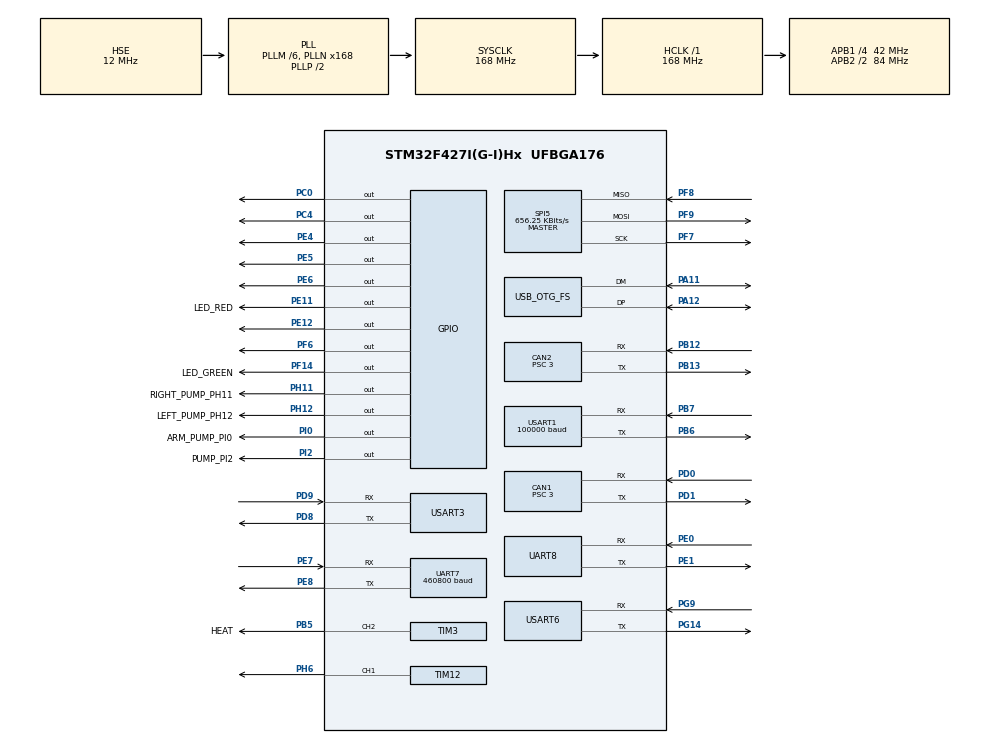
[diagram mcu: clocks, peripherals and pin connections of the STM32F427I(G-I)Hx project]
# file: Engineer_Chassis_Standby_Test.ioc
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CAN1.ABOM=ENABLE
CAN1.AWUM=ENABLE
CAN1.BS1=CAN_BS1_7TQ
CAN1.BS2=CAN_BS2_6TQ
CAN1.CalculateBaudRate=1000000
CAN1.CalculateTimeBit=1000
CAN1.CalculateTimeQuantum=71.42857142857143
CAN1.NART=ENABLE
CAN1.Prescaler=3
CAN1.TXFP=ENABLE
CAN2.ABOM=ENABLE
CAN2.AWUM=ENABLE
CAN2.BS1=CAN_BS1_7TQ
CAN2.BS2=CAN_BS2_6TQ
CAN2.CalculateBaudRate=1000000
CAN2.CalculateTimeBit=1000
CAN2.CalculateTimeQuantum=71.42857142857143
CAN2.NART=ENABLE
CAN2.Prescaler=3
CAN2.TXFP=ENABLE
Dma.Request0=USART1_RX
Dma.Request1=SPI5_RX
Dma.Request2=SPI5_TX
Dma.Request3=UART7_RX
Dma.Request4=UART8_RX
Dma.Request5=UART8_TX
Dma.Request6=USART3_RX
Dma.Request7=USART3_TX
Dma.Request8=USART6_RX
Dma.Request9=USART6_TX
Dma.SPI5_RX.1.Direction=DMA_PERIPH_TO_MEMORY
Dma.SPI5_RX.1.FIFOMode=DMA_FIFOMODE_DISABLE
Dma.SPI5_RX.1.Instance=DMA2_Stream3
Dma.SPI5_RX.1.MemDataAlignment=DMA_MDATAALIGN_BYTE
Dma.SPI5_RX.1.MemInc=DMA_MINC_ENABLE
Dma.SPI5_RX.1.Mode=DMA_NORMAL
Dma.SPI5_RX.1.PeriphDataAlignment=DMA_PDATAALIGN_BYTE
Dma.SPI5_RX.1.PeriphInc=DMA_PINC_DISABLE
Dma.SPI5_RX.1.Priority=DMA_PRIORITY_HIGH
Dma.SPI5_TX.2.Direction=DMA_MEMORY_TO_PERIPH
Dma.SPI5_TX.2.FIFOMode=DMA_FIFOMODE_DISABLE
Dma.SPI5_TX.2.Instance=DMA2_Stream4
Dma.SPI5_TX.2.MemDataAlignment=DMA_MDATAALIGN_BYTE
Dma.SPI5_TX.2.MemInc=DMA_MINC_ENABLE
Dma.SPI5_TX.2.Mode=DMA_NORMAL
Dma.SPI5_TX.2.PeriphDataAlignment=DMA_PDATAALIGN_BYTE
Dma.SPI5_TX.2.PeriphInc=DMA_PINC_DISABLE
Dma.SPI5_TX.2.Priority=DMA_PRIORITY_HIGH
Dma.UART7_RX.3.Direction=DMA_PERIPH_TO_MEMORY
Dma.UART7_RX.3.FIFOMode=DMA_FIFOMODE_DISABLE
Dma.UART7_RX.3.Instance=DMA1_Stream3
Dma.UART7_RX.3.MemDataAlignment=DMA_MDATAALIGN_BYTE
Dma.UART7_RX.3.MemInc=DMA_MINC_ENABLE
Dma.UART7_RX.3.Mode=DMA_NORMAL
Dma.UART7_RX.3.PeriphDataAlignment=DMA_PDATAALIGN_BYTE
Dma.UART7_RX.3.PeriphInc=DMA_PINC_DISABLE
Dma.UART7_RX.3.Priority=DMA_PRIORITY_HIGH
Dma.UART8_RX.4.Direction=DMA_PERIPH_TO_MEMORY
Dma.UART8_RX.4.FIFOMode=DMA_FIFOMODE_DISABLE
Dma.UART8_RX.4.Instance=DMA1_Stream6
Dma.UART8_RX.4.MemDataAlignment=DMA_MDATAALIGN_BYTE
Dma.UART8_RX.4.MemInc=DMA_MINC_ENABLE
Dma.UART8_RX.4.Mode=DMA_CIRCULAR
Dma.UART8_RX.4.PeriphDataAlignment=DMA_PDATAALIGN_BYTE
Dma.UART8_RX.4.PeriphInc=DMA_PINC_DISABLE
Dma.UART8_RX.4.Priority=DMA_PRIORITY_HIGH
Dma.UART8_TX.5.Direction=DMA_MEMORY_TO_PERIPH
Dma.UART8_TX.5.FIFOMode=DMA_FIFOMODE_DISABLE
Dma.UART8_TX.5.Instance=DMA1_Stream0
Dma.UART8_TX.5.MemDataAlignment=DMA_MDATAALIGN_BYTE
Dma.UART8_TX.5.MemInc=DMA_MINC_ENABLE
Dma.UART8_TX.5.Mode=DMA_NORMAL
Dma.UART8_TX.5.PeriphDataAlignment=DMA_PDATAALIGN_BYTE
Dma.UART8_TX.5.PeriphInc=DMA_PINC_DISABLE
Dma.UART8_TX.5.Priority=DMA_PRIORITY_HIGH
Dma.USART1_RX.0.Direction=DMA_PERIPH_TO_MEMORY
Dma.USART1_RX.0.FIFOMode=DMA_FIFOMODE_DISABLE
Dma.USART1_RX.0.Instance=DMA2_Stream2
Dma.USART1_RX.0.MemDataAlignment=DMA_MDATAALIGN_BYTE
Dma.USART1_RX.0.MemInc=DMA_MINC_ENABLE
Dma.USART1_RX.0.Mode=DMA_NORMAL
Dma.USART1_RX.0.PeriphDataAlignment=DMA_PDATAALIGN_BYTE
Dma.USART1_RX.0.PeriphInc=DMA_PINC_DISABLE
Dma.USART1_RX.0.Priority=DMA_PRIORITY_HIGH
Dma.USART3_RX.6.Direction=DMA_PERIPH_TO_MEMORY
Dma.USART3_RX.6.FIFOMode=DMA_FIFOMODE_DISABLE
Dma.USART3_RX.6.Instance=DMA1_Stream1
Dma.USART3_RX.6.MemDataAlignment=DMA_MDATAALIGN_BYTE
Dma.USART3_RX.6.MemInc=DMA_MINC_ENABLE
Dma.USART3_RX.6.Mode=DMA_CIRCULAR
Dma.USART3_RX.6.PeriphDataAlignment=DMA_PDATAALIGN_BYTE
Dma.USART3_RX.6.PeriphInc=DMA_PINC_DISABLE
Dma.USART3_RX.6.Priority=DMA_PRIORITY_HIGH
Dma.USART3_TX.7.Direction=DMA_MEMORY_TO_PERIPH
Dma.USART3_TX.7.FIFOMode=DMA_FIFOMODE_DISABLE
Dma.USART3_TX.7.Instance=DMA1_Stream4
Dma.USART3_TX.7.MemDataAlignment=DMA_MDATAALIGN_BYTE
Dma.USART3_TX.7.MemInc=DMA_MINC_ENABLE
Dma.USART3_TX.7.Mode=DMA_NORMAL
Dma.USART3_TX.7.PeriphDataAlignment=DMA_PDATAALIGN_BYTE
Dma.USART3_TX.7.PeriphInc=DMA_PINC_DISABLE
Dma.USART3_TX.7.Priority=DMA_PRIORITY_HIGH
Dma.USART6_RX.8.Direction=DMA_PERIPH_TO_MEMORY
Dma.USART6_RX.8.FIFOMode=DMA_FIFOMODE_DISABLE
Dma.USART6_RX.8.Instance=DMA2_Stream1
Dma.USART6_RX.8.MemDataAlignment=DMA_MDATAALIGN_BYTE
Dma.USART6_RX.8.MemInc=DMA_MINC_ENABLE
Dma.USART6_RX.8.Mode=DMA_NORMAL
Dma.USART6_RX.8.PeriphDataAlignment=DMA_PDATAALIGN_BYTE
Dma.USART6_RX.8.PeriphInc=DMA_PINC_DISABLE
Dma.USART6_RX.8.Priority=DMA_PRIORITY_HIGH
Dma.USART6_TX.9.Direction=DMA_MEMORY_TO_PERIPH
Dma.USART6_TX.9.FIFOMode=DMA_FIFOMODE_DISABLE
Dma.USART6_TX.9.Instance=DMA2_Stream6
Dma.USART6_TX.9.MemDataAlignment=DMA_MDATAALIGN_BYTE
Dma.USART6_TX.9.MemInc=DMA_MINC_ENABLE
Dma.USART6_TX.9.Mode=DMA_NORMAL
Dma.USART6_TX.9.PeriphDataAlignment=DMA_PDATAALIGN_BYTE
Dma.USART6_TX.9.PeriphInc=DMA_PINC_DISABLE
Dma.USART6_TX.9.Priority=DMA_PRIORITY_HIGH
FREERTOS.BinarySemaphores01=ChassisLFUpdateBinarySem,Dynamic,NULL,Depleted;ChassisLBUpdateBinarySem,Dynamic,NULL,Depleted;ChassisRBUpdateBinarySem,Dynamic,NULL,Depleted;ChassisRFUpdateBinarySem,Dynamic,NULL,Depleted;HI229UMRxBinarySem,Dynamic,NULL,Depleted;TofUpdateBinarySem,Dynamic,NULL,Depleted;GimbalYawUpdateBinarySem,Dynamic,NULL,Depleted;GimbalSlideUpdateBinarySem,Dynamic,NULL,Depleted;ServoCtrlTXBinarySem,Dynamic,NULL,Available;AbsorbUpdateBinarySem,Dynamic,NULL,Available;GimbalToChassisUpdateBinarySem,Dynamic,NULL,Depleted
FREERTOS.CountingSemaphores01=CAN1CountingSem,3,Dynamic,NULL,3;CAN2CountingSem,3,Dynamic,NULL,3
FREERTOS.Queues01=CAN1SendQueue,64,can_tx_member_t,0,Dynamic,NULL,NULL;CAN2SendQueue,64,can_tx_member_t,0,Dynamic,NULL,NULL;ServoCtrlQueue,16,servo_ctrl_data_t,0,Dynamic,NULL,NULL
FREERTOS.Tasks01=defaultTask,24,128,StartDefaultTask,Default,NULL,Dynamic,NULL,NULL;can1_Task,40,256,CAN1_Task,As weak,NULL,Dynamic,NULL,NULL;can2_Task,40,256,CAN2_Task,As weak,NULL,Dynamic,NULL,NULL;chassis_Task,24,256,Chassis_Task,As weak,NULL,Dynamic,NULL,NULL;hi229um_Task,24,128,HI229UM_Task,As weak,NULL,Dynamic,NULL,NULL;tof_check_Task,24,128,Tof_Check_Task,As weak,NULL,Dynamic,NULL,NULL;motor_check,24,128,Motor_Check_Task,As weak,NULL,Dynamic,NULL,NULL;servo_ctrl_Task,24,128,Servo_Ctrl_Task,As weak,NULL,Dynamic,NULL,NULL;gimbal_slide,24,128,Gimbal_Slide_Task,As weak,NULL,Dynamic,NULL,NULL;gimbal_attitude,24,256,Gimbal_Attitude_Task,As weak,NULL,Dynamic,NULL,NULL;info_Task,24,256,Info_Task,As weak,NULL,Dynamic,NULL,NULL;absorb_Task,24,128,Absorb_Task,As weak,NULL,Dynamic,NULL,NULL;check_communi,24,128,Check_Communicate_Task,As weak,NULL,Dynamic,NULL,NULL;communicat_Task,24,128,Communication_Task,As weak,NULL,Dynamic,NULL,NULL
FREERTOS.configTOTAL_HEAP_SIZE=120000
FREERTOS.configUSE_NEWLIB_REENTRANT=1
IWDG.Prescaler=IWDG_PRESCALER_64
IWDG.Reload=625
Mcu.Family=STM32F4
Mcu.Name=STM32F427I(G-I)Hx
Mcu.Package=UFBGA176
NVIC.CAN1_RX0_IRQn=true\:5\:0\:false\:false\:true\:true\:true\:true\:true
NVIC.CAN1_TX_IRQn=true\:5\:0\:false\:false\:true\:true\:true\:true\:true
NVIC.CAN2_RX1_IRQn=true\:5\:0\:false\:false\:true\:true\:true\:true\:true
NVIC.CAN2_TX_IRQn=true\:5\:0\:false\:false\:true\:true\:true\:true\:true
NVIC.DMA1_Stream0_IRQn=true\:5\:0\:false\:false\:true\:true\:false\:true\:true
NVIC.DMA1_Stream1_IRQn=true\:5\:0\:false\:false\:true\:true\:false\:true\:true
NVIC.DMA1_Stream3_IRQn=true\:5\:0\:false\:false\:true\:true\:false\:true\:true
NVIC.DMA1_Stream4_IRQn=true\:5\:0\:false\:false\:true\:true\:false\:true\:true
NVIC.DMA1_Stream6_IRQn=true\:5\:0\:false\:false\:true\:true\:false\:true\:true
NVIC.DMA2_Stream1_IRQn=true\:5\:0\:false\:false\:true\:true\:false\:true\:true
NVIC.DMA2_Stream2_IRQn=true\:5\:0\:false\:false\:true\:true\:false\:true\:true
NVIC.DMA2_Stream3_IRQn=true\:5\:0\:false\:false\:true\:true\:false\:true\:true
NVIC.DMA2_Stream4_IRQn=true\:5\:0\:false\:false\:true\:true\:false\:true\:true
NVIC.DMA2_Stream6_IRQn=true\:5\:0\:false\:false\:true\:true\:false\:true\:true
NVIC.PriorityGroup=NVIC_PRIORITYGROUP_4
NVIC.SPI5_IRQn=true\:5\:0\:false\:false\:true\:true\:true\:true\:true
NVIC.TIM7_IRQn=true\:15\:0\:false\:false\:true\:false\:false\:true\:true
NVIC.TimeBase=TIM7_IRQn
NVIC.TimeBaseIP=TIM7
NVIC.UART7_IRQn=true\:5\:0\:false\:false\:true\:true\:true\:true\:true
NVIC.UART8_IRQn=true\:5\:0\:false\:false\:true\:true\:true\:true\:true
NVIC.USART1_IRQn=true\:5\:0\:false\:false\:true\:true\:true\:true\:true
NVIC.USART3_IRQn=true\:5\:0\:false\:false\:true\:true\:true\:true\:true
NVIC.USART6_IRQn=true\:5\:0\:false\:false\:true\:true\:true\:true\:true
PA11.Mode=Device_Only
PA11.Signal=USB_OTG_FS_DM
PA12.Mode=Device_Only
PA12.Signal=USB_OTG_FS_DP
PA13.Mode=Serial_Wire
PA13.Signal=SYS_JTMS-SWDIO
PA14.Mode=Serial_Wire
PA14.Signal=SYS_JTCK-SWCLK
PB12.Mode=CAN_Activate
PB12.Signal=CAN2_RX
PB13.Mode=CAN_Activate
PB13.Signal=CAN2_TX
PB5.GPIO_Label=HEAT
PB5.GPIO_PuPd=GPIO_PULLUP
PB5.GPIO_Speed=GPIO_SPEED_FREQ_HIGH
PB5.Signal=S_TIM3_CH2
PB6.Mode=Asynchronous
PB6.Signal=USART1_TX
PB7.Mode=Asynchronous
PB7.Signal=USART1_RX
PC0.GPIO_PuPd=GPIO_PULLUP
PC0.GPIO_Speed=GPIO_SPEED_FREQ_HIGH
PC0.Signal=GPIO_Output
PC4.GPIO_PuPd=GPIO_PULLUP
PC4.GPIO_Speed=GPIO_SPEED_FREQ_HIGH
PC4.Signal=GPIO_Output
PD0.Mode=CAN_Activate
PD0.Signal=CAN1_RX
PD1.Mode=CAN_Activate
PD1.Signal=CAN1_TX
PD8.Mode=Asynchronous
PD8.Signal=USART3_TX
PD9.Mode=Asynchronous
PD9.Signal=USART3_RX
PE0.Mode=Asynchronous
PE0.Signal=UART8_RX
PE1.Mode=Asynchronous
PE1.Signal=UART8_TX
PE11.GPIO_Label=LED_RED
PE11.PinState=GPIO_PIN_SET
PE11.Signal=GPIO_Output
PE12.GPIO_PuPd=GPIO_PULLUP
PE12.GPIO_Speed=GPIO_SPEED_FREQ_HIGH
PE12.Signal=GPIO_Output
PE4.GPIO_PuPd=GPIO_PULLUP
PE4.GPIO_Speed=GPIO_SPEED_FREQ_HIGH
PE4.Signal=GPIO_Output
PE5.GPIO_PuPd=GPIO_PULLUP
PE5.GPIO_Speed=GPIO_SPEED_FREQ_HIGH
PE5.Signal=GPIO_Output
PE6.GPIO_PuPd=GPIO_PULLUP
PE6.GPIO_Speed=GPIO_SPEED_FREQ_HIGH
PE6.Signal=GPIO_Output
PE7.Mode=Asynchronous
PE7.Signal=UART7_RX
PE8.Mode=Asynchronous
PE8.Signal=UART7_TX
PF14.GPIO_Label=LED_GREEN
PF14.Signal=GPIO_Output
PF6.Signal=GPIO_Output
PF7.Mode=Full_Duplex_Master
PF7.Signal=SPI5_SCK
PF8.Mode=Full_Duplex_Master
PF8.Signal=SPI5_MISO
PF9.Mode=Full_Duplex_Master
PF9.Signal=SPI5_MOSI
PG14.Mode=Asynchronous
PG14.Signal=USART6_TX
PG9.Mode=Asynchronous
PG9.Signal=USART6_RX
PH0/OSC_IN.Mode=HSE-External-Oscillator
PH0/OSC_IN.Signal=RCC_OSC_IN
PH1/OSC_OUT.Mode=HSE-External-Oscillator
PH1/OSC_OUT.Signal=RCC_OSC_OUT
PH11.GPIO_Label=RIGHT_PUMP_PH11
PH11.GPIO_Speed=GPIO_SPEED_FREQ_HIGH
PH11.Signal=GPIO_Output
PH12.GPIO_Label=LEFT_PUMP_PH12
PH12.GPIO_Speed=GPIO_SPEED_FREQ_HIGH
PH12.Signal=GPIO_Output
PH6.Signal=S_TIM12_CH1
PI0.GPIO_Label=ARM_PUMP_PI0
PI0.Signal=GPIO_Output
PI2.GPIO_Label=PUMP_PI2
PI2.Signal=GPIO_Output
ProjectManager.HeapSize=0x1000
ProjectManager.StackSize=0x1000
ProjectManager.TargetToolchain=STM32CubeIDE
RCC.48MHZClocksFreq_Value=48000000
RCC.AHBFreq_Value=168000000
RCC.APB1CLKDivider=RCC_HCLK_DIV4
RCC.APB1Freq_Value=42000000
RCC.APB1TimFreq_Value=84000000
RCC.APB2CLKDivider=RCC_HCLK_DIV2
RCC.APB2Freq_Value=84000000
RCC.APB2TimFreq_Value=168000000
RCC.CortexFreq_Value=168000000
RCC.HCLKFreq_Value=168000000
RCC.HSE_VALUE=12000000
RCC.HSI_VALUE=16000000
RCC.LSE_VALUE=32768
RCC.PLLM=6
RCC.PLLN=168
RCC.PLLQ=7
RCC.SYSCLKFreq_VALUE=168000000
RCC.SYSCLKSource=RCC_SYSCLKSOURCE_PLLCLK
RCC.VCOOutputFreq_Value=336000000
SH.S_TIM12_CH1.0=TIM12_CH1,PWM Generation1 CH1
SH.S_TIM3_CH2.0=TIM3_CH2,PWM Generation2 CH2
SPI5.BaudRatePrescaler=SPI_BAUDRATEPRESCALER_128
SPI5.CalculateBaudRate=656.25 KBits/s
SPI5.Direction=SPI_DIRECTION_2LINES
SPI5.Mode=SPI_MODE_MASTER
SPI5.VirtualType=VM_MASTER
TIM12.Channel-PWM\ Generation1\ CH1=TIM_CHANNEL_1
TIM12.Period=369
TIM12.Prescaler=83
TIM3.Channel-PWM\ Generation2\ CH2=TIM_CHANNEL_2
TIM3.Period=9999
UART7.BaudRate=460800
UART7.VirtualMode=Asynchronous
UART8.VirtualMode=Asynchronous
USART1.BaudRate=100000
USART1.Parity=PARITY_EVEN
USART1.VirtualMode=VM_ASYNC
USART1.WordLength=WORDLENGTH_9B
USART3.VirtualMode=VM_ASYNC
USART6.VirtualMode=VM_ASYNC
USB_OTG_FS.VirtualMode=Device_Only
VP_FREERTOS_VS_CMSIS_V2.Mode=CMSIS_V2
VP_IWDG_VS_IWDG.Mode=IWDG_Activate
VP_SYS_VS_tim7.Mode=TIM7
VP_TIM12_VS_ClockSourceINT.Mode=Internal
board=custom

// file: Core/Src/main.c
/* USER CODE BEGIN Header */
/**
  ******************************************************************************
  * @file           : main.c
  * @brief          : Main program body
  ******************************************************************************
  * @attention
  *
  * Copyright (c) 2024 STMicroelectronics.
  * All rights reserved.
  *
  * This software is licensed under terms that can be found in the LICENSE file
  * in the root directory of this software component.
  * If no LICENSE file comes with this software, it is provided AS-IS.
  *
  ******************************************************************************
  */
/* USER CODE END Header */
#include "main.h"
#include "cmsis_os.h"
#include "can.h"
#include "dma.h"
#include "iwdg.h"
#include "spi.h"
#include "tim.h"
#include "usart.h"
#include "usb_otg.h"
#include "gpio.h"

/* USER CODE BEGIN Includes */
#include "Compilable.h"
#include "RTOS.h"
/* USER CODE END Includes */

void SystemClock_Config(void);
void MX_FREERTOS_Init(void);

int main(void)
{

  /* USER CODE BEGIN 1 */
  __HAL_RCC_SYSCLK_CONFIG(RCC_SYSCLKSOURCE_HSI);
  /* USER CODE END 1 */

  /* MCU Configuration--------------------------------------------------------*/

  /* Reset of all peripherals, Initializes the Flash interface and the Systick. */
  HAL_Init();

  /* Configure the system clock */
  SystemClock_Config();

  /* Initialize all configured peripherals */
  MX_GPIO_Init();
  MX_DMA_Init();
  MX_USART1_UART_Init();
  MX_TIM12_Init();
  MX_CAN1_Init();
  MX_CAN2_Init();
  MX_SPI5_Init();
  MX_TIM3_Init();
  MX_UART7_Init();
  MX_UART8_Init();
  MX_USART3_UART_Init();
  MX_USART6_UART_Init();
  MX_IWDG_Init();
  MX_USB_OTG_FS_PCD_Init();
  /* USER CODE BEGIN 2 */
  BSP_CAN_Init();
  /* USER CODE END 2 */

  /* Init scheduler */
  osKernelInitialize();

  /* Call init function for freertos objects (in cmsis_os2.c) */
  MX_FREERTOS_Init();

  /* Start scheduler */
  osKernelStart();

  /* We should never get here as control is now taken by the scheduler */

  /* Infinite loop */
  while (1)
  {

  }
}

void SystemClock_Config(void)
{
  RCC_OscInitTypeDef RCC_OscInitStruct = {0};
  RCC_ClkInitTypeDef RCC_ClkInitStruct = {0};

  /** Configure the main internal regulator output voltage
  */
  __HAL_RCC_PWR_CLK_ENABLE();
  __HAL_PWR_VOLTAGESCALING_CONFIG(PWR_REGULATOR_VOLTAGE_SCALE1);

  /** Initializes the RCC Oscillators according to the specified parameters
  * in the RCC_OscInitTypeDef structure.
  */
  RCC_OscInitStruct.OscillatorType = RCC_OSCILLATORTYPE_LSI|RCC_OSCILLATORTYPE_HSE;
  RCC_OscInitStruct.HSEState = RCC_HSE_ON;
  RCC_OscInitStruct.LSIState = RCC_LSI_ON;
  RCC_OscInitStruct.PLL.PLLState = RCC_PLL_ON;
  RCC_OscInitStruct.PLL.PLLSource = RCC_PLLSOURCE_HSE;
  RCC_OscInitStruct.PLL.PLLM = 6;
  RCC_OscInitStruct.PLL.PLLN = 168;
  RCC_OscInitStruct.PLL.PLLP = RCC_PLLP_DIV2;
  RCC_OscInitStruct.PLL.PLLQ = 7;
  if (HAL_RCC_OscConfig(&RCC_OscInitStruct) != HAL_OK)
  {
    Error_Handler();
  }

  /** Initializes the CPU, AHB and APB buses clocks
  */
  RCC_ClkInitStruct.ClockType = RCC_CLOCKTYPE_HCLK|RCC_CLOCKTYPE_SYSCLK
                              |RCC_CLOCKTYPE_PCLK1|RCC_CLOCKTYPE_PCLK2;
  RCC_ClkInitStruct.SYSCLKSource = RCC_SYSCLKSOURCE_PLLCLK;
  RCC_ClkInitStruct.AHBCLKDivider = RCC_SYSCLK_DIV1;
  RCC_ClkInitStruct.APB1CLKDivider = RCC_HCLK_DIV4;
  RCC_ClkInitStruct.APB2CLKDivider = RCC_HCLK_DIV2;

  if (HAL_RCC_ClockConfig(&RCC_ClkInitStruct, FLASH_LATENCY_5) != HAL_OK)
  {
    Error_Handler();
  }
}

void HAL_TIM_PeriodElapsedCallback(TIM_HandleTypeDef *htim)
{
  if (htim->Instance == TIM7) {
    HAL_IncTick();
  }
}

void Error_Handler(void)
{
  __disable_irq();
  while (1)
  {
  }
}

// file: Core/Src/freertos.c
/* USER CODE BEGIN Header */
/**
  ******************************************************************************
  * File Name          : freertos.c
  * Description        : Code for freertos applications
  ******************************************************************************
  * @attention
  *
  * Copyright (c) 2024 STMicroelectronics.
  * All rights reserved.
  *
  * This software is licensed under terms that can be found in the LICENSE file
  * in the root directory of this software component.
  * If no LICENSE file comes with this software, it is provided AS-IS.
  *
  ******************************************************************************
  */
/* USER CODE END Header */

#include "FreeRTOS.h"
#include "task.h"
#include "main.h"
#include "cmsis_os.h"

/* USER CODE BEGIN Includes */
#include "Compilable.h"
#include "iwdg.h"
/* USER CODE END Includes */

/* Definitions for defaultTask */
osThreadId_t defaultTaskHandle;
const osThreadAttr_t defaultTask_attributes = {
  .name = "defaultTask",
  .stack_size = 128 * 4,
  .priority = (osPriority_t) osPriorityNormal,
};
/* Definitions for remotectrl_Task */
osThreadId_t remotectrl_TaskHandle;
const osThreadAttr_t remotectrl_Task_attributes = {
  .name = "remotectrl_Task",
  .stack_size = 128 * 4,
  .priority = (osPriority_t) osPriorityNormal,
};
/* Definitions for can1_Task */
osThreadId_t can1_TaskHandle;
const osThreadAttr_t can1_Task_attributes = {
  .name = "can1_Task",
  .stack_size = 256 * 4,
  .priority = (osPriority_t) osPriorityHigh,
};
/* Definitions for can2_Task */
osThreadId_t can2_TaskHandle;
const osThreadAttr_t can2_Task_attributes = {
  .name = "can2_Task",
  .stack_size = 256 * 4,
  .priority = (osPriority_t) osPriorityHigh,
};
/* Definitions for chassis_Task */
osThreadId_t chassis_TaskHandle;
const osThreadAttr_t chassis_Task_attributes = {
  .name = "chassis_Task",
  .stack_size = 256 * 4,
  .priority = (osPriority_t) osPriorityNormal,
};
/* Definitions for hi229um_Task */
osThreadId_t hi229um_TaskHandle;
const osThreadAttr_t hi229um_Task_attributes = {
  .name = "hi229um_Task",
  .stack_size = 128 * 4,
  .priority = (osPriority_t) osPriorityNormal,
};
/* Definitions for usb_Task */
osThreadId_t usb_TaskHandle;
const osThreadAttr_t usb_Task_attributes = {
  .name = "usb_Task",
  .stack_size = 512 * 4,
  .priority = (osPriority_t) osPriorityNormal,
};
/* Definitions for tof_check_Task */
osThreadId_t tof_check_TaskHandle;
const osThreadAttr_t tof_check_Task_attributes = {
  .name = "tof_check_Task",
  .stack_size = 128 * 4,
  .priority = (osPriority_t) osPriorityNormal,
};
/* Definitions for motor_check */
osThreadId_t motor_checkHandle;
const osThreadAttr_t motor_check_attributes = {
  .name = "motor_check",
  .stack_size = 128 * 4,
  .priority = (osPriority_t) osPriorityNormal,
};
/* Definitions for servo_ctrl_Task */
osThreadId_t servo_ctrl_TaskHandle;
const osThreadAttr_t servo_ctrl_Task_attributes = {
  .name = "servo_ctrl_Task",
  .stack_size = 128 * 4,
  .priority = (osPriority_t) osPriorityNormal,
};
/* Definitions for gimbal_slide */
osThreadId_t gimbal_slideHandle;
const osThreadAttr_t gimbal_slide_attributes = {
  .name = "gimbal_slide",
  .stack_size = 128 * 4,
  .priority = (osPriority_t) osPriorityNormal,
};
/* Definitions for gimbal_attitude */
osThreadId_t gimbal_attitudeHandle;
const osThreadAttr_t gimbal_attitude_attributes = {
  .name = "gimbal_attitude",
  .stack_size = 256 * 4,
  .priority = (osPriority_t) osPriorityNormal,
};
/* Definitions for info_Task */
osThreadId_t info_TaskHandle;
const osThreadAttr_t info_Task_attributes = {
  .name = "info_Task",
  .stack_size = 256 * 4,
  .priority = (osPriority_t) osPriorityNormal,
};
/* Definitions for kb_state_Task */
osThreadId_t kb_state_TaskHandle;
const osThreadAttr_t kb_state_Task_attributes = {
  .name = "kb_state_Task",
  .stack_size = 128 * 4,
  .priority = (osPriority_t) osPriorityNormal,
};
/* Definitions for kb_event_Task */
osThreadId_t kb_event_TaskHandle;
const osThreadAttr_t kb_event_Task_attributes = {
  .name = "kb_event_Task",
  .stack_size = 128 * 4,
  .priority = (osPriority_t) osPriorityNormal,
};
/* Definitions for absorb_Task */
osThreadId_t absorb_TaskHandle;
const osThreadAttr_t absorb_Task_attributes = {
  .name = "absorb_Task",
  .stack_size = 128 * 4,
  .priority = (osPriority_t) osPriorityNormal,
};
/* Definitions for arm_Task */
osThreadId_t arm_TaskHandle;
const osThreadAttr_t arm_Task_attributes = {
  .name = "arm_Task",
  .stack_size = 128 * 4,
  .priority = (osPriority_t) osPriorityNormal,
};
/* Definitions for check_communi */
osThreadId_t check_communiHandle;
const osThreadAttr_t check_communi_attributes = {
  .name = "check_communi",
  .stack_size = 128 * 4,
  .priority = (osPriority_t) osPriorityNormal,
};
/* Definitions for autoctrl_Task */
osThreadId_t autoctrl_TaskHandle;
const osThreadAttr_t autoctrl_Task_attributes = {
  .name = "autoctrl_Task",
  .stack_size = 256 * 4,
  .priority = (osPriority_t) osPriorityNormal,
};
/* Definitions for gyro_info_Task */
osThreadId_t gyro_info_TaskHandle;
const osThreadAttr_t gyro_info_Task_attributes = {
  .name = "gyro_info_Task",
  .stack_size = 128 * 4,
  .priority = (osPriority_t) osPriorityNormal,
};
/* Definitions for CAN1SendQueue */
osMessageQueueId_t CAN1SendQueueHandle;
const osMessageQueueAttr_t CAN1SendQueue_attributes = {
  .name = "CAN1SendQueue"
};
/* Definitions for CAN2SendQueue */
osMessageQueueId_t CAN2SendQueueHandle;
const osMessageQueueAttr_t CAN2SendQueue_attributes = {
  .name = "CAN2SendQueue"
};
/* Definitions for ServoCtrlQueue */
osMessageQueueId_t ServoCtrlQueueHandle;
const osMessageQueueAttr_t ServoCtrlQueue_attributes = {
  .name = "ServoCtrlQueue"
};
/* Definitions for RCUpdateBinarySem */
osSemaphoreId_t RCUpdateBinarySemHandle;
const osSemaphoreAttr_t RCUpdateBinarySem_attributes = {
  .name = "RCUpdateBinarySem"
};
/* Definitions for ChassisLFUpdateBinarySem */
osSemaphoreId_t ChassisLFUpdateBinarySemHandle;
const osSemaphoreAttr_t ChassisLFUpdateBinarySem_attributes = {
  .name = "ChassisLFUpdateBinarySem"
};
/* Definitions for ChassisLBUpdateBinarySem */
osSemaphoreId_t ChassisLBUpdateBinarySemHandle;
const osSemaphoreAttr_t ChassisLBUpdateBinarySem_attributes = {
  .name = "ChassisLBUpdateBinarySem"
};
/* Definitions for ChassisRBUpdateBinarySem */
osSemaphoreId_t ChassisRBUpdateBinarySemHandle;
const osSemaphoreAttr_t ChassisRBUpdateBinarySem_attributes = {
  .name = "ChassisRBUpdateBinarySem"
};
/* Definitions for ChassisRFUpdateBinarySem */
osSemaphoreId_t ChassisRFUpdateBinarySemHandle;
const osSemaphoreAttr_t ChassisRFUpdateBinarySem_attributes = {
  .name = "ChassisRFUpdateBinarySem"
};
/* Definitions for HI229UMRxBinarySem */
osSemaphoreId_t HI229UMRxBinarySemHandle;
const osSemaphoreAttr_t HI229UMRxBinarySem_attributes = {
  .name = "HI229UMRxBinarySem"
};
/* Definitions for IMUDMABinarySem */
osSemaphoreId_t IMUDMABinarySemHandle;
const osSemaphoreAttr_t IMUDMABinarySem_attributes = {
  .name = "IMUDMABinarySem"
};
/* Definitions for TofUpdateBinarySem */
osSemaphoreId_t TofUpdateBinarySemHandle;
const osSemaphoreAttr_t TofUpdateBinarySem_attributes = {
  .name = "TofUpdateBinarySem"
};
/* Definitions for GimbalYawUpdateBinarySem */
osSemaphoreId_t GimbalYawUpdateBinarySemHandle;
const osSemaphoreAttr_t GimbalYawUpdateBinarySem_attributes = {
  .name = "GimbalYawUpdateBinarySem"
};
/* Definitions for GimbalSlideUpdateBinarySem */
osSemaphoreId_t GimbalSlideUpdateBinarySemHandle;
const osSemaphoreAttr_t GimbalSlideUpdateBinarySem_attributes = {
  .name = "GimbalSlideUpdateBinarySem"
};
/* Definitions for ClawUpdateBinarySem */
osSemaphoreId_t ClawUpdateBinarySemHandle;
const osSemaphoreAttr_t ClawUpdateBinarySem_attributes = {
  .name = "ClawUpdateBinarySem"
};
/* Definitions for ServoCtrlTXBinarySem */
osSemaphoreId_t ServoCtrlTXBinarySemHandle;
const osSemaphoreAttr_t ServoCtrlTXBinarySem_attributes = {
  .name = "ServoCtrlTXBinarySem"
};
/* Definitions for AbsorbUpdateBinarySem */
osSemaphoreId_t AbsorbUpdateBinarySemHandle;
const osSemaphoreAttr_t AbsorbUpdateBinarySem_attributes = {
  .name = "AbsorbUpdateBinarySem"
};
/* Definitions for ArmResetInitBinarySem */
osSemaphoreId_t ArmResetInitBinarySemHandle;
const osSemaphoreAttr_t ArmResetInitBinarySem_attributes = {
  .name = "ArmResetInitBinarySem"
};
/* Definitions for ArmUpdateBinarySem */
osSemaphoreId_t ArmUpdateBinarySemHandle;
const osSemaphoreAttr_t ArmUpdateBinarySem_attributes = {
  .name = "ArmUpdateBinarySem"
};
/* Definitions for JudgementInitBinarySem */
osSemaphoreId_t JudgementInitBinarySemHandle;
const osSemaphoreAttr_t JudgementInitBinarySem_attributes = {
  .name = "JudgementInitBinarySem"
};
/* Definitions for GyroInfoUpdateBinarySem */
osSemaphoreId_t GyroInfoUpdateBinarySemHandle;
const osSemaphoreAttr_t GyroInfoUpdateBinarySem_attributes = {
  .name = "GyroInfoUpdateBinarySem"
};
/* Definitions for CAN1CountingSem */
osSemaphoreId_t CAN1CountingSemHandle;
const osSemaphoreAttr_t CAN1CountingSem_attributes = {
  .name = "CAN1CountingSem"
};
/* Definitions for CAN2CountingSem */
osSemaphoreId_t CAN2CountingSemHandle;
const osSemaphoreAttr_t CAN2CountingSem_attributes = {
  .name = "CAN2CountingSem"
};
/* Definitions for RefereeEvent */
osEventFlagsId_t RefereeEventHandle;
const osEventFlagsAttr_t RefereeEvent_attributes = {
  .name = "RefereeEvent"
};
/* Definitions for refereeEvent */
osEventFlagsId_t refereeEventHandle;
const osEventFlagsAttr_t refereeEvent_attributes = {
  .name = "refereeEvent"
};

void StartDefaultTask(void *argument);
void RemoteCtrl_Task(void *argument);
void CAN1_Task(void *argument);
void CAN2_Task(void *argument);
void Chassis_Task(void *argument);
void HI229UM_Task(void *argument);
void USB_Task(void *argument);
void Tof_Check_Task(void *argument);
void Motor_Check_Task(void *argument);
void Servo_Ctrl_Task(void *argument);
void Gimbal_Slide_Task(void *argument);
void Gimbal_Attitude_Task(void *argument);
void Info_Task(void *argument);
void KB_State_Task(void *argument);
void KB_Event_Task(void *argument);
void Absorb_Task(void *argument);
void Arm_Task(void *argument);
void Check_Communicate_Task(void *argument);
void AutoCtrl_Task(void *argument);
void Gyro_Info_Task(void *argument);

extern void MX_USB_DEVICE_Init(void);
void MX_FREERTOS_Init(void); /* (MISRA C 2004 rule 8.1) */

void MX_FREERTOS_Init(void) {

  /* Create the semaphores(s) */
  /* creation of RCUpdateBinarySem */
  RCUpdateBinarySemHandle = osSemaphoreNew(1, 0, &RCUpdateBinarySem_attributes);

  /* creation of ChassisLFUpdateBinarySem */
  ChassisLFUpdateBinarySemHandle = osSemaphoreNew(1, 0, &ChassisLFUpdateBinarySem_attributes);

  /* creation of ChassisLBUpdateBinarySem */
  ChassisLBUpdateBinarySemHandle = osSemaphoreNew(1, 0, &ChassisLBUpdateBinarySem_attributes);

  /* creation of ChassisRBUpdateBinarySem */
  ChassisRBUpdateBinarySemHandle = osSemaphoreNew(1, 0, &ChassisRBUpdateBinarySem_attributes);

  /* creation of ChassisRFUpdateBinarySem */
  ChassisRFUpdateBinarySemHandle = osSemaphoreNew(1, 0, &ChassisRFUpdateBinarySem_attributes);

  /* creation of HI229UMRxBinarySem */
  HI229UMRxBinarySemHandle = osSemaphoreNew(1, 0, &HI229UMRxBinarySem_attributes);

  /* creation of IMUDMABinarySem */
  IMUDMABinarySemHandle = osSemaphoreNew(1, 0, &IMUDMABinarySem_attributes);

  /* creation of TofUpdateBinarySem */
  TofUpdateBinarySemHandle = osSemaphoreNew(1, 0, &TofUpdateBinarySem_attributes);

  /* creation of GimbalYawUpdateBinarySem */
  GimbalYawUpdateBinarySemHandle = osSemaphoreNew(1, 0, &GimbalYawUpdateBinarySem_attributes);

  /* creation of GimbalSlideUpdateBinarySem */
  GimbalSlideUpdateBinarySemHandle = osSemaphoreNew(1, 0, &GimbalSlideUpdateBinarySem_attributes);

  /* creation of ClawUpdateBinarySem */
  ClawUpdateBinarySemHandle = osSemaphoreNew(1, 0, &ClawUpdateBinarySem_attributes);

  /* creation of ServoCtrlTXBinarySem */
  ServoCtrlTXBinarySemHandle = osSemaphoreNew(1, 1, &ServoCtrlTXBinarySem_attributes);

  /* creation of AbsorbUpdateBinarySem */
  AbsorbUpdateBinarySemHandle = osSemaphoreNew(1, 1, &AbsorbUpdateBinarySem_attributes);

  /* creation of ArmResetInitBinarySem */
  ArmResetInitBinarySemHandle = osSemaphoreNew(1, 1, &ArmResetInitBinarySem_attributes);

  /* creation of ArmUpdateBinarySem */
  ArmUpdateBinarySemHandle = osSemaphoreNew(1, 1, &ArmUpdateBinarySem_attributes);

  /* creation of JudgementInitBinarySem */
  JudgementInitBinarySemHandle = osSemaphoreNew(1, 1, &JudgementInitBinarySem_attributes);

  /* creation of GyroInfoUpdateBinarySem */
  GyroInfoUpdateBinarySemHandle = osSemaphoreNew(1, 1, &GyroInfoUpdateBinarySem_attributes);

  /* creation of CAN1CountingSem */
  CAN1CountingSemHandle = osSemaphoreNew(3, 3, &CAN1CountingSem_attributes);

  /* creation of CAN2CountingSem */
  CAN2CountingSemHandle = osSemaphoreNew(3, 3, &CAN2CountingSem_attributes);

  /* Create the queue(s) */
  /* creation of CAN1SendQueue */
  CAN1SendQueueHandle = osMessageQueueNew (64, sizeof(can_tx_member_t), &CAN1SendQueue_attributes);

  /* creation of CAN2SendQueue */
  CAN2SendQueueHandle = osMessageQueueNew (64, sizeof(can_tx_member_t), &CAN2SendQueue_attributes);

  /* creation of ServoCtrlQueue */
  ServoCtrlQueueHandle = osMessageQueueNew (16, sizeof(servo_ctrl_data_t), &ServoCtrlQueue_attributes);

  /* Create the thread(s) */
  /* creation of defaultTask */
  defaultTaskHandle = osThreadNew(StartDefaultTask, NULL, &defaultTask_attributes);

  /* creation of remotectrl_Task */
  remotectrl_TaskHandle = osThreadNew(RemoteCtrl_Task, NULL, &remotectrl_Task_attributes);

  /* creation of can1_Task */
  can1_TaskHandle = osThreadNew(CAN1_Task, NULL, &can1_Task_attributes);

  /* creation of can2_Task */
  can2_TaskHandle = osThreadNew(CAN2_Task, NULL, &can2_Task_attributes);

  /* creation of chassis_Task */
  chassis_TaskHandle = osThreadNew(Chassis_Task, NULL, &chassis_Task_attributes);

  /* creation of hi229um_Task */
  hi229um_TaskHandle = osThreadNew(HI229UM_Task, NULL, &hi229um_Task_attributes);

  /* creation of usb_Task */
  usb_TaskHandle = osThreadNew(USB_Task, NULL, &usb_Task_attributes);

  /* creation of tof_check_Task */
  tof_check_TaskHandle = osThreadNew(Tof_Check_Task, NULL, &tof_check_Task_attributes);

  /* creation of motor_check */
  motor_checkHandle = osThreadNew(Motor_Check_Task, NULL, &motor_check_attributes);

  /* creation of servo_ctrl_Task */
  servo_ctrl_TaskHandle = osThreadNew(Servo_Ctrl_Task, NULL, &servo_ctrl_Task_attributes);

  /* creation of gimbal_slide */
  gimbal_slideHandle = osThreadNew(Gimbal_Slide_Task, NULL, &gimbal_slide_attributes);

  /* creation of gimbal_attitude */
  gimbal_attitudeHandle = osThreadNew(Gimbal_Attitude_Task, NULL, &gimbal_attitude_attributes);

  /* creation of info_Task */
  info_TaskHandle = osThreadNew(Info_Task, NULL, &info_Task_attributes);

  /* creation of kb_state_Task */
  kb_state_TaskHandle = osThreadNew(KB_State_Task, NULL, &kb_state_Task_attributes);

  /* creation of kb_event_Task */
  kb_event_TaskHandle = osThreadNew(KB_Event_Task, NULL, &kb_event_Task_attributes);

  /* creation of absorb_Task */
  absorb_TaskHandle = osThreadNew(Absorb_Task, NULL, &absorb_Task_attributes);

  /* creation of arm_Task */
  arm_TaskHandle = osThreadNew(Arm_Task, NULL, &arm_Task_attributes);

  /* creation of check_communi */
  check_communiHandle = osThreadNew(Check_Communicate_Task, NULL, &check_communi_attributes);

  /* creation of autoctrl_Task */
  autoctrl_TaskHandle = osThreadNew(AutoCtrl_Task, NULL, &autoctrl_Task_attributes);

  /* creation of gyro_info_Task */
  gyro_info_TaskHandle = osThreadNew(Gyro_Info_Task, NULL, &gyro_info_Task_attributes);

  /* Create the event(s) */
  /* creation of RefereeEvent */
  RefereeEventHandle = osEventFlagsNew(&RefereeEvent_attributes);

  /* creation of refereeEvent */
  refereeEventHandle = osEventFlagsNew(&refereeEvent_attributes);

}

void StartDefaultTask(void *argument)
{
  /* init code for USB_DEVICE */
  MX_USB_DEVICE_Init();
  /* USER CODE BEGIN StartDefaultTask */
  /* Infinite loop */
  for(;;)
  {
    HAL_IWDG_Refresh(&hiwdg);
    HAL_GPIO_TogglePin(LED_GREEN_GPIO_Port,LED_GREEN_Pin);
    osDelay(500);
  }
  /* USER CODE END StartDefaultTask */
}

__weak void RemoteCtrl_Task(void *argument)
{
  for(;;)
  {
    osDelay(1);
  }
}

__weak void CAN1_Task(void *argument)
{
  for(;;)
  {
    osDelay(1);
  }
}

__weak void CAN2_Task(void *argument)
{
  for(;;)
  {
    osDelay(1);
  }
}

__weak void Chassis_Task(void *argument)
{
  for(;;)
  {
    osDelay(1);
  }
}

__weak void HI229UM_Task(void *argument)
{
  for(;;)
  {
    osDelay(1);
  }
}

__weak void USB_Task(void *argument)
{
  for(;;)
  {
    osDelay(1);
  }
}

__weak void Tof_Check_Task(void *argument)
{
  for(;;)
  {
    osDelay(1);
  }
}

__weak void Motor_Check_Task(void *argument)
{
  for(;;)
  {
    osDelay(1);
  }
}

__weak void Servo_Ctrl_Task(void *argument)
{
  for(;;)
  {
    osDelay(1);
  }
}

__weak void Gimbal_Slide_Task(void *argument)
{
  for(;;)
  {
    osDelay(1);
  }
}

__weak void Gimbal_Attitude_Task(void *argument)
{
  for(;;)
  {
    osDelay(1);
  }
}

__weak void Info_Task(void *argument)
{
  for(;;)
  {
    osDelay(1);
  }
}

__weak void KB_State_Task(void *argument)
{
  for(;;)
  {
    osDelay(1);
  }
}

__weak void KB_Event_Task(void *argument)
{
  for(;;)
  {
    osDelay(1);
  }
}

__weak void Absorb_Task(void *argument)
{
  for(;;)
  {
    osDelay(1);
  }
}

__weak void Arm_Task(void *argument)
{
  for(;;)
  {
    osDelay(1);
  }
}

__weak void Check_Communicate_Task(void *argument)
{
  for(;;)
  {
    osDelay(1);
  }
}

__weak void AutoCtrl_Task(void *argument)
{
  for(;;)
  {
    osDelay(1);
  }
}

__weak void Gyro_Info_Task(void *argument)
{
  for(;;)
  {
    osDelay(1);
  }
}
